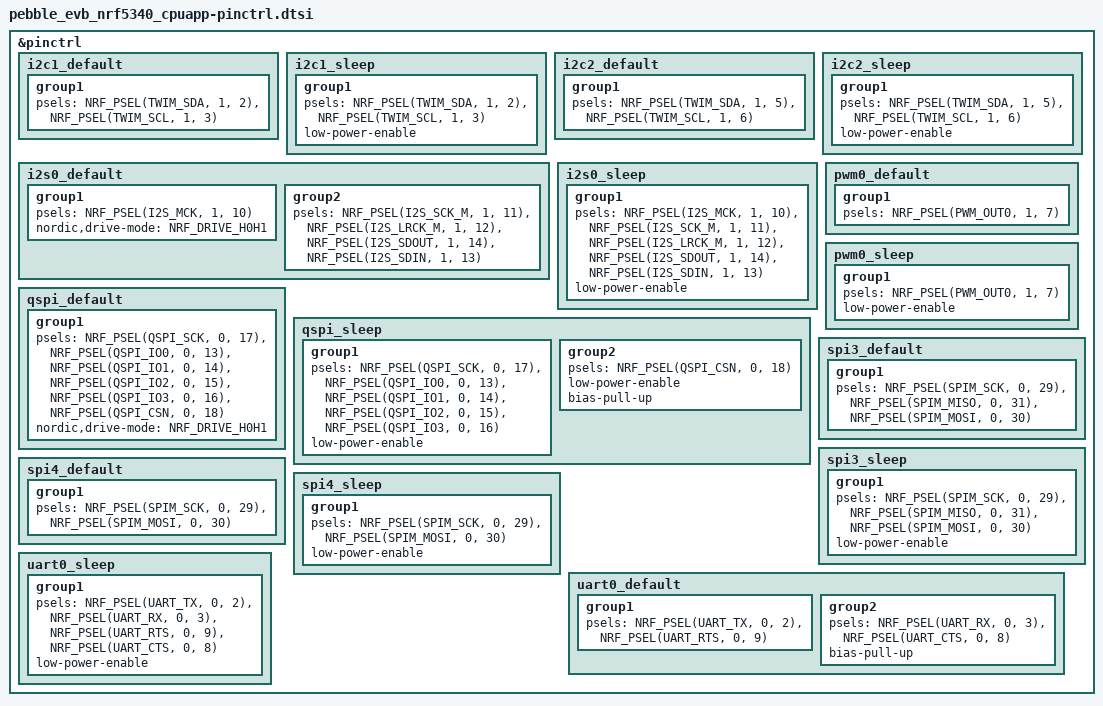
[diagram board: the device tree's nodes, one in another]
&pinctrl {
	i2c1_default: i2c1_default {
		group1 {
			psels = <NRF_PSEL(TWIM_SDA, 1, 2)>,
				<NRF_PSEL(TWIM_SCL, 1, 3)>;
		};
	};

	i2c1_sleep: i2c1_sleep {
		group1 {
			psels = <NRF_PSEL(TWIM_SDA, 1, 2)>,
				<NRF_PSEL(TWIM_SCL, 1, 3)>;
			low-power-enable;
		};
	};

	i2c2_default: i2c2_default {
		group1 {
			psels = <NRF_PSEL(TWIM_SDA, 1, 5)>,
				<NRF_PSEL(TWIM_SCL, 1, 6)>;
		};
	};

	i2c2_sleep: i2c2_sleep {
		group1 {
			psels = <NRF_PSEL(TWIM_SDA, 1, 5)>,
				<NRF_PSEL(TWIM_SCL, 1, 6)>;
			low-power-enable;
		};
	};

	i2s0_default: i2s0_default {
		group1 {
			psels = <NRF_PSEL(I2S_MCK, 1, 10)>;
			nordic,drive-mode = <NRF_DRIVE_H0H1>;
		};
		group2 {
			psels = <NRF_PSEL(I2S_SCK_M, 1, 11)>,
				<NRF_PSEL(I2S_LRCK_M, 1, 12)>,
				<NRF_PSEL(I2S_SDOUT, 1, 14)>,
				<NRF_PSEL(I2S_SDIN, 1, 13)>;
		};
	};

	i2s0_sleep: i2s0_sleep {
		group1 {
			psels = <NRF_PSEL(I2S_MCK, 1, 10)>,
				<NRF_PSEL(I2S_SCK_M, 1, 11)>,
				<NRF_PSEL(I2S_LRCK_M, 1, 12)>,
				<NRF_PSEL(I2S_SDOUT, 1, 14)>,
				<NRF_PSEL(I2S_SDIN, 1, 13)>;
			low-power-enable;
		};
	};

	pwm0_default: pwm0_default {
		group1 {
			psels = <NRF_PSEL(PWM_OUT0, 1, 7)>;
		};
	};

	pwm0_sleep: pwm0_sleep {
		group1 {
			psels = <NRF_PSEL(PWM_OUT0, 1, 7)>;
			low-power-enable;
		};
	};

	qspi_default: qspi_default {
		group1 {
			psels = <NRF_PSEL(QSPI_SCK, 0, 17)>,
				<NRF_PSEL(QSPI_IO0, 0, 13)>,
				<NRF_PSEL(QSPI_IO1, 0, 14)>,
				<NRF_PSEL(QSPI_IO2, 0, 15)>,
				<NRF_PSEL(QSPI_IO3, 0, 16)>,
				<NRF_PSEL(QSPI_CSN, 0, 18)>;
			nordic,drive-mode = <NRF_DRIVE_H0H1>;
		};
	};

	qspi_sleep: qspi_sleep {
		group1 {
			psels = <NRF_PSEL(QSPI_SCK, 0, 17)>,
				<NRF_PSEL(QSPI_IO0, 0, 13)>,
				<NRF_PSEL(QSPI_IO1, 0, 14)>,
				<NRF_PSEL(QSPI_IO2, 0, 15)>,
				<NRF_PSEL(QSPI_IO3, 0, 16)>;
			low-power-enable;
		};
		group2 {
			psels = <NRF_PSEL(QSPI_CSN, 0, 18)>;
			low-power-enable;
			bias-pull-up;
		};
	};

	spi3_default: spi3_default {
		group1 {
			psels = <NRF_PSEL(SPIM_SCK, 0, 29)>,
				<NRF_PSEL(SPIM_MISO, 0, 31)>,
				<NRF_PSEL(SPIM_MOSI, 0, 30)>;
		};
	};

	spi3_sleep: spi3_sleep {
		group1 {
			psels = <NRF_PSEL(SPIM_SCK, 0, 29)>,
				<NRF_PSEL(SPIM_MISO, 0, 31)>,
				<NRF_PSEL(SPIM_MOSI, 0, 30)>;
			low-power-enable;
		};
	};

	spi4_default: spi4_default {
		group1 {
			psels = <NRF_PSEL(SPIM_SCK, 0, 29)>,
				<NRF_PSEL(SPIM_MOSI, 0, 30)>;
		};
	};

	spi4_sleep: spi4_sleep {
		group1 {
			psels = <NRF_PSEL(SPIM_SCK, 0, 29)>,
				<NRF_PSEL(SPIM_MOSI, 0, 30)>;
			low-power-enable;
		};
	};

	uart0_default: uart0_default {
		group1 {
			psels = <NRF_PSEL(UART_TX, 0, 2)>,
				<NRF_PSEL(UART_RTS, 0, 9)>;
		};
		group2 {
			psels = <NRF_PSEL(UART_RX, 0, 3)>,
				<NRF_PSEL(UART_CTS, 0, 8)>;
			bias-pull-up;
		};
	};

	uart0_sleep: uart0_sleep {
		group1 {
			psels = <NRF_PSEL(UART_TX, 0, 2)>,
				<NRF_PSEL(UART_RX, 0, 3)>,
				<NRF_PSEL(UART_RTS, 0, 9)>,
				<NRF_PSEL(UART_CTS, 0, 8)>;
			low-power-enable;
		};
	};
};
